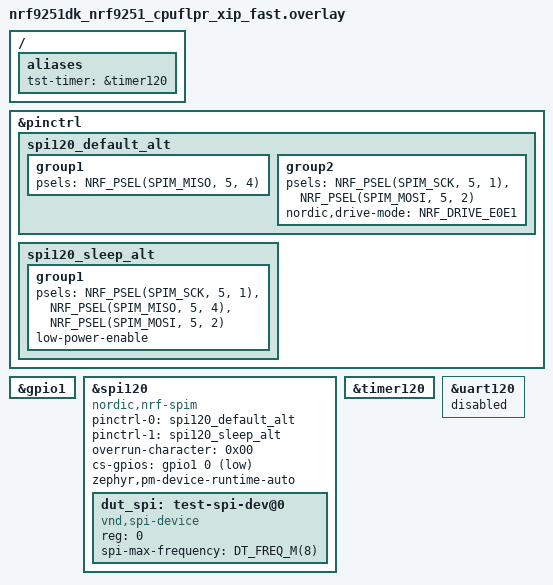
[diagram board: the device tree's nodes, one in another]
/*
 * Copyright (c) 2026 Nordic Semiconductor ASA
 *
 * SPDX-License-Identifier: LicenseRef-Nordic-5-Clause
 */

/* Required loopbacks:
 * P5.04 <-> P5.02
 */

/ {
	aliases {
		tst-timer = &timer120;
	};
};

&pinctrl {
	spi120_default_alt: spi120_default_alt {
		group1 {
			psels = <NRF_PSEL(SPIM_MISO, 5, 4)>;
		};

		group2 {
			psels = <NRF_PSEL(SPIM_SCK, 5, 1)>,
				<NRF_PSEL(SPIM_MOSI, 5, 2)>;
			nordic,drive-mode = <NRF_DRIVE_E0E1>;
		};
	};

	spi120_sleep_alt: spi120_sleep_alt {
		group1 {
			psels = <NRF_PSEL(SPIM_SCK, 5, 1)>,
				<NRF_PSEL(SPIM_MISO, 5, 4)>,
				<NRF_PSEL(SPIM_MOSI, 5, 2)>;
			low-power-enable;
		};
	};
};

&gpio1 {
	status = "okay";
};

&spi120 {
	compatible = "nordic,nrf-spim";
	status = "okay";
	pinctrl-0 = <&spi120_default_alt>;
	pinctrl-1 = <&spi120_sleep_alt>;
	pinctrl-names = "default", "sleep";
	overrun-character = <0x00>;
	cs-gpios = <&gpio1 0 GPIO_ACTIVE_LOW>;
	zephyr,pm-device-runtime-auto;

	dut_spi: test-spi-dev@0 {
		compatible = "vnd,spi-device";
		reg = <0>;
		spi-max-frequency = <DT_FREQ_M(8)>;
	};
};

&timer120 {
	status = "okay";
};

&uart120 {
	status = "disabled";
};
